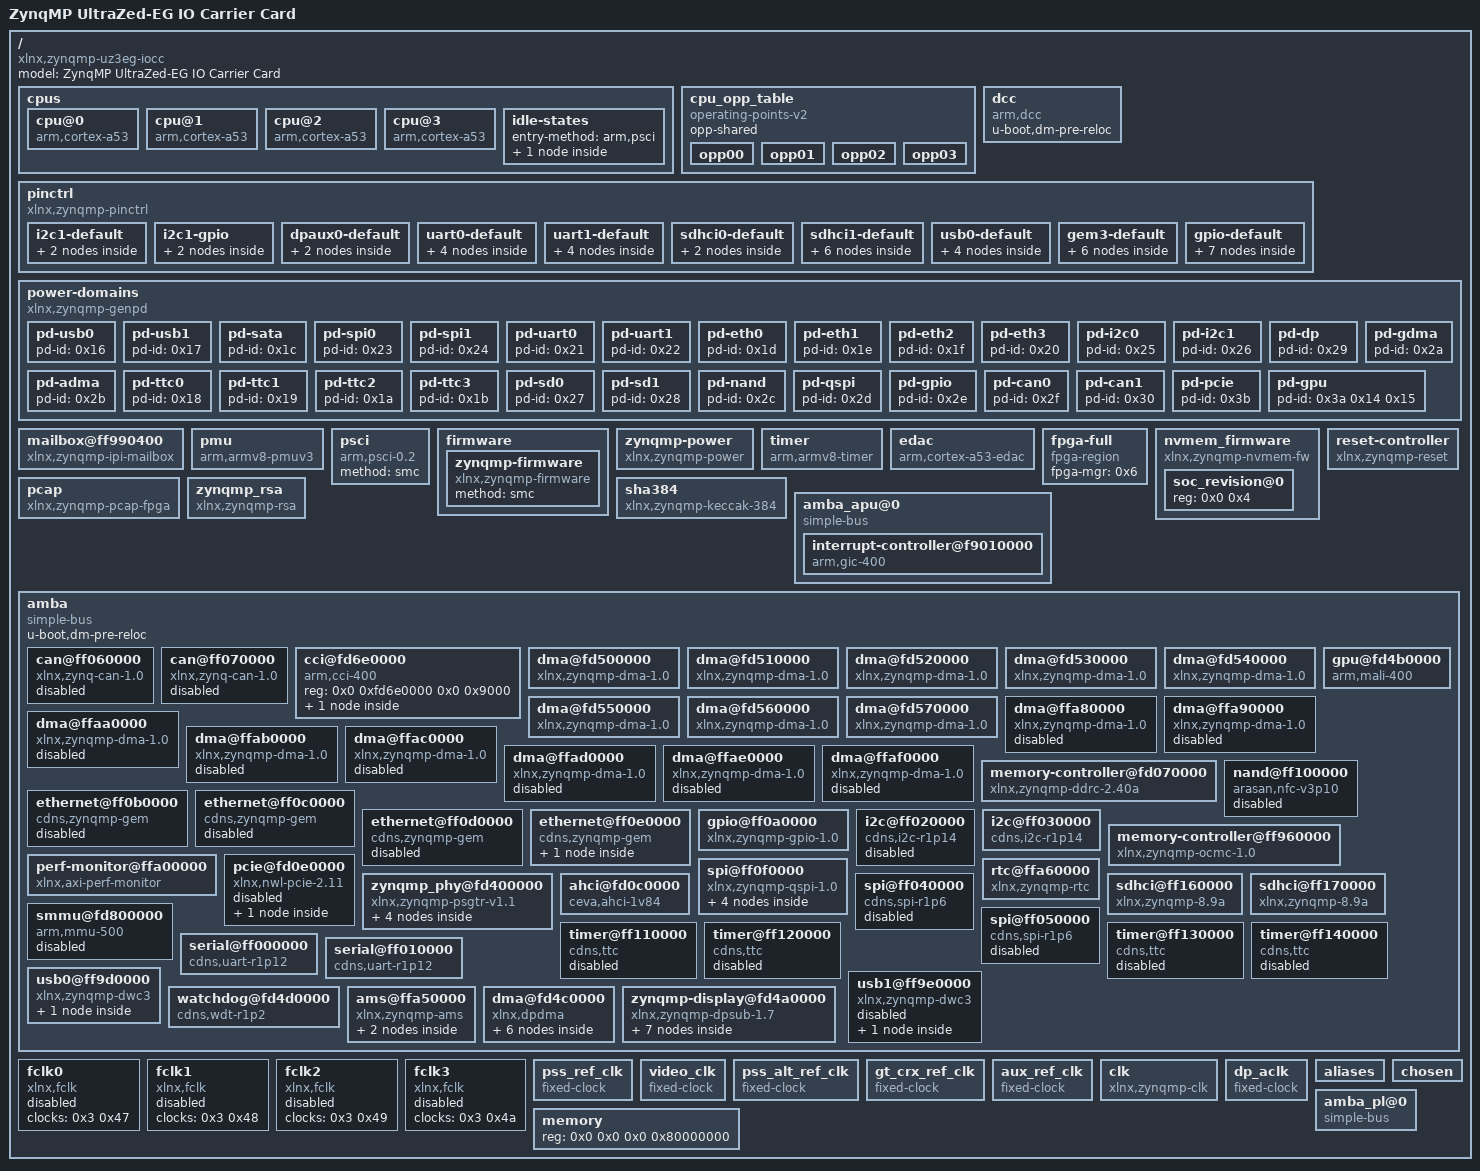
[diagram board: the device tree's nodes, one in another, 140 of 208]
/dts-v1/;

/ {
	compatible = "xlnx,zynqmp-uz3eg-iocc", "xlnx,zynqmp";
	#address-cells = <0x2>;
	#size-cells = <0x2>;
	model = "ZynqMP UltraZed-EG IO Carrier Card";

	cpus {
		#address-cells = <0x1>;
		#size-cells = <0x0>;

		cpu@0 {
			compatible = "arm,cortex-a53", "arm,armv8";
			device_type = "cpu";
			enable-method = "psci";
			operating-points-v2 = <0x1>;
			reg = <0x0>;
			cpu-idle-states = <0x2>;
			clocks = <0x3 0xa>;
			linux,phandle = <0x41>;
			phandle = <0x41>;
		};

		cpu@1 {
			compatible = "arm,cortex-a53", "arm,armv8";
			device_type = "cpu";
			enable-method = "psci";
			reg = <0x1>;
			operating-points-v2 = <0x1>;
			cpu-idle-states = <0x2>;
			linux,phandle = <0x42>;
			phandle = <0x42>;
		};

		cpu@2 {
			compatible = "arm,cortex-a53", "arm,armv8";
			device_type = "cpu";
			enable-method = "psci";
			reg = <0x2>;
			operating-points-v2 = <0x1>;
			cpu-idle-states = <0x2>;
			linux,phandle = <0x43>;
			phandle = <0x43>;
		};

		cpu@3 {
			compatible = "arm,cortex-a53", "arm,armv8";
			device_type = "cpu";
			enable-method = "psci";
			reg = <0x3>;
			operating-points-v2 = <0x1>;
			cpu-idle-states = <0x2>;
			linux,phandle = <0x44>;
			phandle = <0x44>;
		};

		idle-states {
			entry-method = "arm,psci";

			cpu-sleep-0 {
				compatible = "arm,idle-state";
				arm,psci-suspend-param = <0x40000000>;
				local-timer-stop;
				entry-latency-us = <0x12c>;
				exit-latency-us = <0x258>;
				min-residency-us = <0x2710>;
				linux,phandle = <0x2>;
				phandle = <0x2>;
			};
		};
	};

	cpu_opp_table {
		compatible = "operating-points-v2";
		opp-shared;
		linux,phandle = <0x1>;
		phandle = <0x1>;

		opp00 {
			opp-hz = <0x0 0x47868bf4>;
			opp-microvolt = <0xf4240>;
			clock-latency-ns = <0x7a120>;
		};

		opp01 {
			opp-hz = <0x0 0x23c345fa>;
			opp-microvolt = <0xf4240>;
			clock-latency-ns = <0x7a120>;
		};

		opp02 {
			opp-hz = <0x0 0x17d783fc>;
			opp-microvolt = <0xf4240>;
			clock-latency-ns = <0x7a120>;
		};

		opp03 {
			opp-hz = <0x0 0x11e1a2fd>;
			opp-microvolt = <0xf4240>;
			clock-latency-ns = <0x7a120>;
		};
	};

	dcc {
		compatible = "arm,dcc";
		status = "okay";
		u-boot,dm-pre-reloc;
		linux,phandle = <0x45>;
		phandle = <0x45>;
	};

	pinctrl {
		compatible = "xlnx,zynqmp-pinctrl";
		status = "okay";
		linux,phandle = <0x46>;
		phandle = <0x46>;

		i2c1-default {
			linux,phandle = <0x17>;
			phandle = <0x17>;

			mux {
				groups = "i2c1_6_grp";
				function = "i2c1";
			};

			conf {
				groups = "i2c1_6_grp";
				bias-pull-up;
				slew-rate = <0x1>;
				io-standard = <0x1>;
			};
		};

		i2c1-gpio {
			linux,phandle = <0x18>;
			phandle = <0x18>;

			mux {
				groups = "gpio0_24_grp", "gpio0_25_grp";
				function = "gpio0";
			};

			conf {
				groups = "gpio0_24_grp", "gpio0_25_grp";
				slew-rate = <0x1>;
				io-standard = <0x1>;
			};
		};

		dpaux0-default {
			linux,phandle = <0x47>;
			phandle = <0x47>;

			mux {
				groups = "dpaux0_0_grp";
				function = "dpaux0";
			};

			conf {
				groups = "dpaux0_0_grp";
				slew-rate = <0x1>;
				io-standard = <0x1>;
			};
		};

		uart0-default {
			linux,phandle = <0x2d>;
			phandle = <0x2d>;

			mux {
				groups = "uart0_8_grp";
				function = "uart0";
			};

			conf {
				groups = "uart0_8_grp";
				slew-rate = <0x1>;
				io-standard = <0x1>;
			};

			conf-rx {
				pins = "MIO34";
				bias-high-impedance;
			};

			conf-tx {
				pins = "MIO35";
				bias-disable;
			};
		};

		uart1-default {
			linux,phandle = <0x2f>;
			phandle = <0x2f>;

			mux {
				groups = "uart1_8_grp";
				function = "uart1";
			};

			conf {
				groups = "uart1_8_grp";
				slew-rate = <0x1>;
				io-standard = <0x1>;
			};

			conf-rx {
				pins = "MIO33";
				bias-high-impedance;
			};

			conf-tx {
				pins = "MIO32";
				bias-disable;
			};
		};

		sdhci0-default {
			linux,phandle = <0x23>;
			phandle = <0x23>;

			mux {
				groups = "sdio0_0_grp";
				function = "sdio0";
			};

			conf {
				groups = "sdio0_0_grp";
				slew-rate = <0x1>;
				io-standard = <0x1>;
				bias-disable;
			};
		};

		sdhci1-default {
			linux,phandle = <0x25>;
			phandle = <0x25>;

			mux {
				groups = "sdio1_pc_0_grp";
				function = "sdio1_pc";
			};

			conf {
				groups = "sdio1_pc_0_grp";
				slew-rate = <0x1>;
				io-standard = <0x1>;
				bias-disable;
			};

			mux-cd {
				groups = "sdio1_cd_0_grp";
				function = "sdio1_cd";
			};

			conf-cd {
				groups = "sdio1_cd_0_grp";
				bias-high-impedance;
				bias-pull-up;
				slew-rate = <0x1>;
				io-standard = <0x1>;
			};

			mux-wp {
				groups = "sdio1_wp_0_grp";
				function = "sdio1_wp";
			};

			conf-wp {
				groups = "sdio1_wp_0_grp";
				bias-high-impedance;
				bias-pull-up;
				slew-rate = <0x1>;
				io-standard = <0x1>;
			};
		};

		usb0-default {
			linux,phandle = <0x31>;
			phandle = <0x31>;

			mux {
				groups = "usb0_0_grp";
				function = "usb0";
			};

			conf {
				groups = "usb0_0_grp";
				slew-rate = <0x1>;
				io-standard = <0x1>;
			};

			conf-rx {
				pins = "MIO52", "MIO53", "MIO55";
				bias-high-impedance;
			};

			conf-tx {
				pins = "MIO54", "MIO56", "MIO57", "MIO58", "MIO59", "MIO60", "MIO61", "MIO62", "MIO63";
				bias-disable;
			};
		};

		gem3-default {
			linux,phandle = <0x48>;
			phandle = <0x48>;

			mux {
				function = "ethernet3";
				groups = "ethernet3_0_grp";
			};

			conf {
				groups = "ethernet3_0_grp";
				slew-rate = <0x1>;
				io-standard = <0x1>;
			};

			conf-rx {
				pins = "MIO70", "MIO71", "MIO72", "MIO73", "MIO74", "MIO75";
				bias-high-impedance;
				low-power-disable;
			};

			conf-tx {
				pins = "MIO64", "MIO65", "MIO66", "MIO67", "MIO68", "MIO69";
				bias-disable;
				low-power-enable;
			};

			mux-mdio {
				function = "mdio3";
				groups = "mdio3_0_grp";
			};

			conf-mdio {
				groups = "mdio3_0_grp";
				slew-rate = <0x1>;
				io-standard = <0x1>;
				bias-disable;
			};
		};

		gpio-default {
			linux,phandle = <0x14>;
			phandle = <0x14>;

			mux {
				function = "gpio0";
				groups = "gpio0_23_grp", "gpio0_36_grp", "gpio0_37_grp", "gpio0_38_grp", "gpio0_39_grp", "gpio0_40_grp", "gpio0_41_grp", "gpio0_42_grp";
			};

			conf {
				groups = "gpio0_23_grp", "gpio0_36_grp", "gpio0_37_grp", "gpio0_38_grp", "gpio0_39_grp", "gpio0_40_grp", "gpio0_41_grp", "gpio0_42_grp";
				slew-rate = <0x1>;
				io-standard = <0x1>;
			};

			conf-pull-up {
				pins = "MIO23", "MIO26", "MIO31", "MIO36", "MIO37", "MIO38", "MIO39", "MIO40", "MIO41", "MIO42";
				bias-pull-up;
			};

			mux-sw {
				function = "gpio0";
				groups = "gpio0_26_grp";
			};

			conf-sw {
				groups = "gpio0_26_grp";
				slew-rate = <0x1>;
				io-standard = <0x1>;
			};

			mux-led {
				function = "gpio0";
				groups = "gpio0_31_grp";
			};

			conf-led {
				groups = "gpio0_31_grp";
				slew-rate = <0x1>;
				io-standard = <0x1>;
			};
		};
	};

	power-domains {
		compatible = "xlnx,zynqmp-genpd";

		pd-usb0 {
			#power-domain-cells = <0x0>;
			pd-id = <0x16>;
			linux,phandle = <0x30>;
			phandle = <0x30>;
		};

		pd-usb1 {
			#power-domain-cells = <0x0>;
			pd-id = <0x17>;
			linux,phandle = <0x33>;
			phandle = <0x33>;
		};

		pd-sata {
			#power-domain-cells = <0x0>;
			pd-id = <0x1c>;
			linux,phandle = <0x20>;
			phandle = <0x20>;
		};

		pd-spi0 {
			#power-domain-cells = <0x0>;
			pd-id = <0x23>;
			linux,phandle = <0x26>;
			phandle = <0x26>;
		};

		pd-spi1 {
			#power-domain-cells = <0x0>;
			pd-id = <0x24>;
			linux,phandle = <0x27>;
			phandle = <0x27>;
		};

		pd-uart0 {
			#power-domain-cells = <0x0>;
			pd-id = <0x21>;
			linux,phandle = <0x2c>;
			phandle = <0x2c>;
		};

		pd-uart1 {
			#power-domain-cells = <0x0>;
			pd-id = <0x22>;
			linux,phandle = <0x2e>;
			phandle = <0x2e>;
		};

		pd-eth0 {
			#power-domain-cells = <0x0>;
			pd-id = <0x1d>;
			linux,phandle = <0xe>;
			phandle = <0xe>;
		};

		pd-eth1 {
			#power-domain-cells = <0x0>;
			pd-id = <0x1e>;
			linux,phandle = <0xf>;
			phandle = <0xf>;
		};

		pd-eth2 {
			#power-domain-cells = <0x0>;
			pd-id = <0x1f>;
			linux,phandle = <0x10>;
			phandle = <0x10>;
		};

		pd-eth3 {
			#power-domain-cells = <0x0>;
			pd-id = <0x20>;
			linux,phandle = <0x11>;
			phandle = <0x11>;
		};

		pd-i2c0 {
			#power-domain-cells = <0x0>;
			pd-id = <0x25>;
			linux,phandle = <0x15>;
			phandle = <0x15>;
		};

		pd-i2c1 {
			#power-domain-cells = <0x0>;
			pd-id = <0x26>;
			linux,phandle = <0x16>;
			phandle = <0x16>;
		};

		pd-dp {
			#power-domain-cells = <0x0>;
			pd-id = <0x29>;
			linux,phandle = <0x34>;
			phandle = <0x34>;
		};

		pd-gdma {
			#power-domain-cells = <0x0>;
			pd-id = <0x2a>;
			linux,phandle = <0xa>;
			phandle = <0xa>;
		};

		pd-adma {
			#power-domain-cells = <0x0>;
			pd-id = <0x2b>;
			linux,phandle = <0xc>;
			phandle = <0xc>;
		};

		pd-ttc0 {
			#power-domain-cells = <0x0>;
			pd-id = <0x18>;
			linux,phandle = <0x28>;
			phandle = <0x28>;
		};

		pd-ttc1 {
			#power-domain-cells = <0x0>;
			pd-id = <0x19>;
			linux,phandle = <0x29>;
			phandle = <0x29>;
		};

		pd-ttc2 {
			#power-domain-cells = <0x0>;
			pd-id = <0x1a>;
			linux,phandle = <0x2a>;
			phandle = <0x2a>;
		};

		pd-ttc3 {
			#power-domain-cells = <0x0>;
			pd-id = <0x1b>;
			linux,phandle = <0x2b>;
			phandle = <0x2b>;
		};

		pd-sd0 {
			#power-domain-cells = <0x0>;
			pd-id = <0x27>;
			linux,phandle = <0x22>;
			phandle = <0x22>;
		};

		pd-sd1 {
			#power-domain-cells = <0x0>;
			pd-id = <0x28>;
			linux,phandle = <0x24>;
			phandle = <0x24>;
		};

		pd-nand {
			#power-domain-cells = <0x0>;
			pd-id = <0x2c>;
			linux,phandle = <0xd>;
			phandle = <0xd>;
		};

		pd-qspi {
			#power-domain-cells = <0x0>;
			pd-id = <0x2d>;
			linux,phandle = <0x1d>;
			phandle = <0x1d>;
		};

		pd-gpio {
			#power-domain-cells = <0x0>;
			pd-id = <0x2e>;
			linux,phandle = <0x13>;
			phandle = <0x13>;
		};

		pd-can0 {
			#power-domain-cells = <0x0>;
			pd-id = <0x2f>;
			linux,phandle = <0x7>;
			phandle = <0x7>;
		};

		pd-can1 {
			#power-domain-cells = <0x0>;
			pd-id = <0x30>;
			linux,phandle = <0x8>;
			phandle = <0x8>;
		};

		pd-pcie {
			#power-domain-cells = <0x0>;
			pd-id = <0x3b>;
			linux,phandle = <0x1c>;
			phandle = <0x1c>;
		};

		pd-gpu {
			#power-domain-cells = <0x0>;
			pd-id = <0x3a 0x14 0x15>;
			linux,phandle = <0xb>;
			phandle = <0xb>;
		};
	};

	mailbox@ff990400 {
		compatible = "xlnx,zynqmp-ipi-mailbox";
		reg = <0x0 0xff9905c0 0x0 0x20 0x0 0xff9905e0 0x0 0x20 0x0 0xff990e80 0x0 0x20 0x0 0xff990ea0 0x0 0x20>;
		reg-names = "local_request_region", "local_response_region", "remote_request_region", "remote_response_region";
		#mbox-cells = <0x1>;
		xlnx,ipi-ids = <0x0 0x4>;
		interrupt-parent = <0x4>;
		interrupts = <0x0 0x23 0x4>;
		linux,phandle = <0x5>;
		phandle = <0x5>;
	};

	pmu {
		compatible = "arm,armv8-pmuv3";
		interrupt-parent = <0x4>;
		interrupts = <0x0 0x8f 0x4 0x0 0x90 0x4 0x0 0x91 0x4 0x0 0x92 0x4>;
	};

	psci {
		compatible = "arm,psci-0.2";
		method = "smc";
	};

	firmware {

		zynqmp-firmware {
			compatible = "xlnx,zynqmp-firmware";
			method = "smc";
			linux,phandle = <0x49>;
			phandle = <0x49>;
		};
	};

	zynqmp-power {
		compatible = "xlnx,zynqmp-power";
		mboxes = <0x5 0x0 0x5 0x1>;
		mbox-names = "tx", "rx";
		linux,phandle = <0x4a>;
		phandle = <0x4a>;
	};

	timer {
		compatible = "arm,armv8-timer";
		interrupt-parent = <0x4>;
		interrupts = <0x1 0xd 0xf08 0x1 0xe 0xf08 0x1 0xb 0xf08 0x1 0xa 0xf08>;
	};

	edac {
		compatible = "arm,cortex-a53-edac";
	};

	fpga-full {
		compatible = "fpga-region";
		fpga-mgr = <0x6>;
		#address-cells = <0x2>;
		#size-cells = <0x2>;
		linux,phandle = <0x4b>;
		phandle = <0x4b>;
	};

	nvmem_firmware {
		compatible = "xlnx,zynqmp-nvmem-fw";
		#address-cells = <0x1>;
		#size-cells = <0x1>;

		soc_revision@0 {
			reg = <0x0 0x4>;
			linux,phandle = <0x1e>;
			phandle = <0x1e>;
		};
	};

	pcap {
		compatible = "xlnx,zynqmp-pcap-fpga";
		linux,phandle = <0x6>;
		phandle = <0x6>;
	};

	reset-controller {
		compatible = "xlnx,zynqmp-reset";
		#reset-cells = <0x1>;
		linux,phandle = <0x1f>;
		phandle = <0x1f>;
	};

	zynqmp_rsa {
		compatible = "xlnx,zynqmp-rsa";
		linux,phandle = <0x4c>;
		phandle = <0x4c>;
	};

	sha384 {
		compatible = "xlnx,zynqmp-keccak-384";
		linux,phandle = <0x4d>;
		phandle = <0x4d>;
	};

	amba_apu@0 {
		compatible = "simple-bus";
		#address-cells = <0x2>;
		#size-cells = <0x1>;
		ranges = <0x0 0x0 0x0 0x0 0xffffffff>;
		linux,phandle = <0x4e>;
		phandle = <0x4e>;

		interrupt-controller@f9010000 {
			compatible = "arm,gic-400", "arm,cortex-a15-gic";
			#interrupt-cells = <0x3>;
			reg = <0x0 0xf9010000 0x10000 0x0 0xf9020000 0x20000 0x0 0xf9040000 0x20000 0x0 0xf9060000 0x20000>;
			interrupt-controller;
			interrupt-parent = <0x4>;
			interrupts = <0x1 0x9 0xf04>;
			linux,phandle = <0x4>;
			phandle = <0x4>;
		};
	};

	amba {
		compatible = "simple-bus";
		u-boot,dm-pre-reloc;
		#address-cells = <0x2>;
		#size-cells = <0x2>;
		ranges;
		linux,phandle = <0x4f>;
		phandle = <0x4f>;

		can@ff060000 {
			compatible = "xlnx,zynq-can-1.0";
			status = "disabled";
			clock-names = "can_clk", "pclk";
			reg = <0x0 0xff060000 0x0 0x1000>;
			interrupts = <0x0 0x17 0x4>;
			interrupt-parent = <0x4>;
			tx-fifo-depth = <0x40>;
			rx-fifo-depth = <0x40>;
			power-domains = <0x7>;
			clocks = <0x3 0x3f 0x3 0x1f>;
			linux,phandle = <0x50>;
			phandle = <0x50>;
		};

		can@ff070000 {
			compatible = "xlnx,zynq-can-1.0";
			status = "disabled";
			clock-names = "can_clk", "pclk";
			reg = <0x0 0xff070000 0x0 0x1000>;
			interrupts = <0x0 0x18 0x4>;
			interrupt-parent = <0x4>;
			tx-fifo-depth = <0x40>;
			rx-fifo-depth = <0x40>;
			power-domains = <0x8>;
			clocks = <0x3 0x40 0x3 0x1f>;
			linux,phandle = <0x51>;
			phandle = <0x51>;
		};

		cci@fd6e0000 {
			compatible = "arm,cci-400";
			reg = <0x0 0xfd6e0000 0x0 0x9000>;
			ranges = <0x0 0x0 0xfd6e0000 0x10000>;
			#address-cells = <0x1>;
			#size-cells = <0x1>;
			linux,phandle = <0x52>;
			phandle = <0x52>;

			pmu@9000 {
				compatible = "arm,cci-400-pmu,r1";
				reg = <0x9000 0x5000>;
				interrupt-parent = <0x4>;
				interrupts = <0x0 0x7b 0x4 0x0 0x7b 0x4 0x0 0x7b 0x4 0x0 0x7b 0x4 0x0 0x7b 0x4>;
			};
		};

		dma@fd500000 {
			status = "okay";
			compatible = "xlnx,zynqmp-dma-1.0";
			reg = <0x0 0xfd500000 0x0 0x1000>;
			interrupt-parent = <0x4>;
			interrupts = <0x0 0x7c 0x4>;
			clock-names = "clk_main", "clk_apb";
			xlnx,bus-width = <0x80>;
			#stream-id-cells = <0x1>;
			iommus = <0x9 0x14e8>;
			power-domains = <0xa>;
			clocks = <0x3 0x13 0x3 0x1f>;
			linux,phandle = <0x53>;
			phandle = <0x53>;
		};

		dma@fd510000 {
			status = "okay";
			compatible = "xlnx,zynqmp-dma-1.0";
			reg = <0x0 0xfd510000 0x0 0x1000>;
			interrupt-parent = <0x4>;
			interrupts = <0x0 0x7d 0x4>;
			clock-names = "clk_main", "clk_apb";
			xlnx,bus-width = <0x80>;
			#stream-id-cells = <0x1>;
			iommus = <0x9 0x14e9>;
			power-domains = <0xa>;
			clocks = <0x3 0x13 0x3 0x1f>;
			linux,phandle = <0x54>;
			phandle = <0x54>;
		};

		dma@fd520000 {
			status = "okay";
			compatible = "xlnx,zynqmp-dma-1.0";
			reg = <0x0 0xfd520000 0x0 0x1000>;
			interrupt-parent = <0x4>;
			interrupts = <0x0 0x7e 0x4>;
			clock-names = "clk_main", "clk_apb";
			xlnx,bus-width = <0x80>;
			#stream-id-cells = <0x1>;
			iommus = <0x9 0x14ea>;
			power-domains = <0xa>;
			clocks = <0x3 0x13 0x3 0x1f>;
			linux,phandle = <0x55>;
			phandle = <0x55>;
		};

		dma@fd530000 {
			status = "okay";
			compatible = "xlnx,zynqmp-dma-1.0";
			reg = <0x0 0xfd530000 0x0 0x1000>;
			interrupt-parent = <0x4>;
			interrupts = <0x0 0x7f 0x4>;
			clock-names = "clk_main", "clk_apb";
			xlnx,bus-width = <0x80>;
			#stream-id-cells = <0x1>;
			iommus = <0x9 0x14eb>;
			power-domains = <0xa>;
			clocks = <0x3 0x13 0x3 0x1f>;
			linux,phandle = <0x56>;
			phandle = <0x56>;
		};

		dma@fd540000 {
			status = "okay";
			compatible = "xlnx,zynqmp-dma-1.0";
			reg = <0x0 0xfd540000 0x0 0x1000>;
			interrupt-parent = <0x4>;
			interrupts = <0x0 0x80 0x4>;
			clock-names = "clk_main", "clk_apb";
			xlnx,bus-width = <0x80>;
			#stream-id-cells = <0x1>;
			iommus = <0x9 0x14ec>;
			power-domains = <0xa>;
			clocks = <0x3 0x13 0x3 0x1f>;
			linux,phandle = <0x57>;
			phandle = <0x57>;
		};

		dma@fd550000 {
			status = "okay";
			compatible = "xlnx,zynqmp-dma-1.0";
			reg = <0x0 0xfd550000 0x0 0x1000>;
			interrupt-parent = <0x4>;
			interrupts = <0x0 0x81 0x4>;
			clock-names = "clk_main", "clk_apb";
			xlnx,bus-width = <0x80>;
			#stream-id-cells = <0x1>;
			iommus = <0x9 0x14ed>;
			power-domains = <0xa>;
			clocks = <0x3 0x13 0x3 0x1f>;
			linux,phandle = <0x58>;
			phandle = <0x58>;
		};

		dma@fd560000 {
			status = "okay";
			compatible = "xlnx,zynqmp-dma-1.0";
			reg = <0x0 0xfd560000 0x0 0x1000>;
			interrupt-parent = <0x4>;
			interrupts = <0x0 0x82 0x4>;
			clock-names = "clk_main", "clk_apb";
			xlnx,bus-width = <0x80>;
			#stream-id-cells = <0x1>;
			iommus = <0x9 0x14ee>;
			power-domains = <0xa>;
			clocks = <0x3 0x13 0x3 0x1f>;
			linux,phandle = <0x59>;
			phandle = <0x59>;
		};

		dma@fd570000 {
			status = "okay";
			compatible = "xlnx,zynqmp-dma-1.0";
			reg = <0x0 0xfd570000 0x0 0x1000>;
			interrupt-parent = <0x4>;
			interrupts = <0x0 0x83 0x4>;
			clock-names = "clk_main", "clk_apb";
			xlnx,bus-width = <0x80>;
			#stream-id-cells = <0x1>;
			iommus = <0x9 0x14ef>;
			power-domains = <0xa>;
			clocks = <0x3 0x13 0x3 0x1f>;
			linux,phandle = <0x5a>;
			phandle = <0x5a>;
		};

		gpu@fd4b0000 {
			status = "okay";
			compatible = "arm,mali-400", "arm,mali-utgard";
			reg = <0x0 0xfd4b0000 0x0 0x10000>;
			interrupt-parent = <0x4>;
			interrupts = <0x0 0x84 0x4 0x0 0x84 0x4 0x0 0x84 0x4 0x0 0x84 0x4 0x0 0x84 0x4 0x0 0x84 0x4>;
			interrupt-names = "IRQGP", "IRQGPMMU", "IRQPP0", "IRQPPMMU0", "IRQPP1", "IRQPPMMU1";
			clock-names = "gpu", "gpu_pp0", "gpu_pp1";
			power-domains = <0xb>;
			clocks = <0x3 0x18 0x3 0x19 0x3 0x1a>;
			linux,phandle = <0x5b>;
			phandle = <0x5b>;
		};

		dma@ffa80000 {
			status = "disabled";
			compatible = "xlnx,zynqmp-dma-1.0";
			reg = <0x0 0xffa80000 0x0 0x1000>;
			interrupt-parent = <0x4>;
			interrupts = <0x0 0x4d 0x4>;
			clock-names = "clk_main", "clk_apb";
			xlnx,bus-width = <0x40>;
			#stream-id-cells = <0x1>;
			power-domains = <0xc>;
			clocks = <0x3 0x44 0x3 0x1f>;
			linux,phandle = <0x5c>;
			phandle = <0x5c>;
		};

		dma@ffa90000 {
			status = "disabled";
			compatible = "xlnx,zynqmp-dma-1.0";
			reg = <0x0 0xffa90000 0x0 0x1000>;
			interrupt-parent = <0x4>;
			interrupts = <0x0 0x4e 0x4>;
			clock-names = "clk_main", "clk_apb";
			xlnx,bus-width = <0x40>;
			#stream-id-cells = <0x1>;
			power-domains = <0xc>;
			clocks = <0x3 0x44 0x3 0x1f>;
			linux,phandle = <0x5d>;
			phandle = <0x5d>;
		};

		dma@ffaa0000 {
			status = "disabled";
			compatible = "xlnx,zynqmp-dma-1.0";
			reg = <0x0 0xffaa0000 0x0 0x1000>;
			interrupt-parent = <0x4>;
			interrupts = <0x0 0x4f 0x4>;
			clock-names = "clk_main", "clk_apb";
			xlnx,bus-width = <0x40>;
			#stream-id-cells = <0x1>;
			power-domains = <0xc>;
			clocks = <0x3 0x44 0x3 0x1f>;
			linux,phandle = <0x5e>;
			phandle = <0x5e>;
		};

		dma@ffab0000 {
			status = "disabled";
			compatible = "xlnx,zynqmp-dma-1.0";
			reg = <0x0 0xffab0000 0x0 0x1000>;
			interrupt-parent = <0x4>;
			interrupts = <0x0 0x50 0x4>;
			clock-names = "clk_main", "clk_apb";
			xlnx,bus-width = <0x40>;
			#stream-id-cells = <0x1>;
			power-domains = <0xc>;
			clocks = <0x3 0x44 0x3 0x1f>;
			linux,phandle = <0x5f>;
			phandle = <0x5f>;
		};

		dma@ffac0000 {
			status = "disabled";
			compatible = "xlnx,zynqmp-dma-1.0";
			reg = <0x0 0xffac0000 0x0 0x1000>;
			interrupt-parent = <0x4>;
			interrupts = <0x0 0x51 0x4>;
			clock-names = "clk_main", "clk_apb";
			xlnx,bus-width = <0x40>;
			#stream-id-cells = <0x1>;
			power-domains = <0xc>;
			clocks = <0x3 0x44 0x3 0x1f>;
			linux,phandle = <0x60>;
			phandle = <0x60>;
		};

		dma@ffad0000 {
			status = "disabled";
			compatible = "xlnx,zynqmp-dma-1.0";
			reg = <0x0 0xffad0000 0x0 0x1000>;
			interrupt-parent = <0x4>;
			interrupts = <0x0 0x52 0x4>;
			clock-names = "clk_main", "clk_apb";
			xlnx,bus-width = <0x40>;
			#stream-id-cells = <0x1>;
			power-domains = <0xc>;
			clocks = <0x3 0x44 0x3 0x1f>;
			linux,phandle = <0x61>;
			phandle = <0x61>;
		};

		dma@ffae0000 {
			status = "disabled";
			compatible = "xlnx,zynqmp-dma-1.0";
			reg = <0x0 0xffae0000 0x0 0x1000>;
			interrupt-parent = <0x4>;
			interrupts = <0x0 0x53 0x4>;
			clock-names = "clk_main", "clk_apb";
			xlnx,bus-width = <0x40>;
			#stream-id-cells = <0x1>;
			power-domains = <0xc>;
			clocks = <0x3 0x44 0x3 0x1f>;
			linux,phandle = <0x62>;
			phandle = <0x62>;
		};

		dma@ffaf0000 {
			status = "disabled";
			compatible = "xlnx,zynqmp-dma-1.0";
			reg = <0x0 0xffaf0000 0x0 0x1000>;
			interrupt-parent = <0x4>;
			interrupts = <0x0 0x54 0x4>;
			clock-names = "clk_main", "clk_apb";
			xlnx,bus-width = <0x40>;
			#stream-id-cells = <0x1>;
			power-domains = <0xc>;
			clocks = <0x3 0x44 0x3 0x1f>;
			linux,phandle = <0x63>;
			phandle = <0x63>;
		};

		memory-controller@fd070000 {
			compatible = "xlnx,zynqmp-ddrc-2.40a";
			reg = <0x0 0xfd070000 0x0 0x30000>;
			interrupt-parent = <0x4>;
			interrupts = <0x0 0x70 0x4>;
			linux,phandle = <0x64>;
			phandle = <0x64>;
		};

		nand@ff100000 {
			compatible = "arasan,nfc-v3p10";
			status = "disabled";
			reg = <0x0 0xff100000 0x0 0x1000>;
			clock-names = "clk_sys", "clk_flash";
			interrupt-parent = <0x4>;
			interrupts = <0x0 0xe 0x4>;
			#address-cells = <0x1>;
			#size-cells = <0x0>;
			#stream-id-cells = <0x1>;
			iommus = <0x9 0x872>;
			power-domains = <0xd>;
			clocks = <0x3 0x3c 0x3 0x1f>;
			linux,phandle = <0x65>;
			phandle = <0x65>;
		};

		ethernet@ff0b0000 {
			compatible = "cdns,zynqmp-gem", "cdns,gem";
			status = "disabled";
			interrupt-parent = <0x4>;
			interrupts = <0x0 0x39 0x4 0x0 0x39 0x4>;
			reg = <0x0 0xff0b0000 0x0 0x1000>;
			clock-names = "pclk", "hclk", "tx_clk", "rx_clk", "tsu_clk";
			#address-cells = <0x1>;
			#size-cells = <0x0>;
			#stream-id-cells = <0x1>;
			iommus = <0x9 0x874>;
			power-domains = <0xe>;
			clocks = <0x3 0x1f 0x3 0x31 0x3 0x2d 0x3 0x31 0x3 0x2c>;
			linux,phandle = <0x66>;
			phandle = <0x66>;
		};

		ethernet@ff0c0000 {
			compatible = "cdns,zynqmp-gem", "cdns,gem";
			status = "disabled";
			interrupt-parent = <0x4>;
			interrupts = <0x0 0x3b 0x4 0x0 0x3b 0x4>;
			reg = <0x0 0xff0c0000 0x0 0x1000>;
			clock-names = "pclk", "hclk", "tx_clk", "rx_clk", "tsu_clk";
			#address-cells = <0x1>;
			#size-cells = <0x0>;
			#stream-id-cells = <0x1>;
			iommus = <0x9 0x875>;
			power-domains = <0xf>;
			clocks = <0x3 0x1f 0x3 0x32 0x3 0x2e 0x3 0x32 0x3 0x2c>;
			linux,phandle = <0x67>;
			phandle = <0x67>;
		};

		ethernet@ff0d0000 {
			compatible = "cdns,zynqmp-gem", "cdns,gem";
			status = "disabled";
			interrupt-parent = <0x4>;
			interrupts = <0x0 0x3d 0x4 0x0 0x3d 0x4>;
			reg = <0x0 0xff0d0000 0x0 0x1000>;
			clock-names = "pclk", "hclk", "tx_clk", "rx_clk", "tsu_clk";
			#address-cells = <0x1>;
			#size-cells = <0x0>;
			#stream-id-cells = <0x1>;
			iommus = <0x9 0x876>;
			power-domains = <0x10>;
			clocks = <0x3 0x1f 0x3 0x33 0x3 0x2f 0x3 0x33 0x3 0x2c>;
			linux,phandle = <0x68>;
			phandle = <0x68>;
		};

		ethernet@ff0e0000 {
			compatible = "cdns,zynqmp-gem", "cdns,gem";
			status = "okay";
			interrupt-parent = <0x4>;
			interrupts = <0x0 0x3f 0x4 0x0 0x3f 0x4>;
			reg = <0x0 0xff0e0000 0x0 0x1000>;
			clock-names = "pclk", "hclk", "tx_clk", "rx_clk", "tsu_clk";
			#address-cells = <0x1>;
			#size-cells = <0x0>;
			#stream-id-cells = <0x1>;
			iommus = <0x9 0x877>;
			power-domains = <0x11>;
			clocks = <0x3 0x1f 0x3 0x34 0x3 0x30 0x3 0x34 0x3 0x2c>;
			xlnx,ptp-enet-clock = <0x0>;
			phy-mode = "rgmii-id";
			phy-handle = <0x12>;
			linux,phandle = <0x69>;
			phandle = <0x69>;

			phy@9 {
				reg = <0x9>;
				ti,rx-internal-delay = <0x8>;
				ti,tx-internal-delay = <0xa>;
				ti,fifo-depth = <0x1>;
				ti,rxctrl-strap-worka;
				linux,phandle = <0x12>;
				phandle = <0x12>;
			};
		};

		gpio@ff0a0000 {
			compatible = "xlnx,zynqmp-gpio-1.0";
			status = "okay";
			#gpio-cells = <0x2>;
			interrupt-parent = <0x4>;
			interrupts = <0x0 0x10 0x4>;
			interrupt-controller;
			#interrupt-cells = <0x2>;
			reg = <0x0 0xff0a0000 0x0 0x1000>;
			gpio-controller;
			power-domains = <0x13>;
			clocks = <0x3 0x1f>;
			pinctrl-names = "default";
			pinctrl-0 = <0x14>;
			linux,phandle = <0x19>;
			phandle = <0x19>;
		};

		i2c@ff020000 {
			compatible = "cdns,i2c-r1p14", "cdns,i2c-r1p10";
			status = "disabled";
			interrupt-parent = <0x4>;
			interrupts = <0x0 0x11 0x4>;
			reg = <0x0 0xff020000 0x0 0x1000>;
			#address-cells = <0x1>;
			#size-cells = <0x0>;
			power-domains = <0x15>;
			clocks = <0x3 0x3d>;
			linux,phandle = <0x6a>;
			phandle = <0x6a>;
		};

		i2c@ff030000 {
			compatible = "cdns,i2c-r1p14", "cdns,i2c-r1p10";
			status = "okay";
			interrupt-parent = <0x4>;
			interrupts = <0x0 0x12 0x4>;
			reg = <0x0 0xff030000 0x0 0x1000>;
			#address-cells = <0x1>;
			#size-cells = <0x0>;
			power-domains = <0x16>;
			clocks = <0x3 0x3e>;
			clock-frequency = <0x61a80>;
			pinctrl-names = "default", "gpio";
			pinctrl-0 = <0x17>;
			pinctrl-1 = <0x18>;
			scl-gpios = <0x19 0x18 0x0>;
			sda-gpios = <0x19 0x19 0x0>;
			linux,phandle = <0x6b>;
			phandle = <0x6b>;
		};

		memory-controller@ff960000 {
			compatible = "xlnx,zynqmp-ocmc-1.0";
			reg = <0x0 0xff960000 0x0 0x1000>;
			interrupt-parent = <0x4>;
			interrupts = <0x0 0xa 0x4>;
			linux,phandle = <0x6c>;
			phandle = <0x6c>;
		};

		perf-monitor@ffa00000 {
			compatible = "xlnx,axi-perf-monitor";
			reg = <0x0 0xffa00000 0x0 0x10000>;
			interrupts = <0x0 0x19 0x4>;
			interrupt-parent = <0x4>;
			xlnx,enable-profile = <0x0>;
			xlnx,enable-trace = <0x0>;
			xlnx,num-monitor-slots = <0x4>;
			xlnx,enable-event-count = <0x1>;
			xlnx,enable-event-log = <0x1>;
			xlnx,have-sampled-metric-cnt = <0x1>;
			xlnx,num-of-counters = <0x8>;
			xlnx,metric-count-width = <0x20>;
			xlnx,metrics-sample-count-width = <0x20>;
			xlnx,global-count-width = <0x20>;
			xlnx,metric-count-scale = <0x1>;
			clocks = <0x3 0x1f>;
			linux,phandle = <0x6d>;
			phandle = <0x6d>;
		};

		pcie@fd0e0000 {
			compatible = "xlnx,nwl-pcie-2.11";
			status = "disabled";
			#address-cells = <0x3>;
			#size-cells = <0x2>;
			#interrupt-cells = <0x1>;
			msi-controller;
			device_type = "pci";
			interrupt-parent = <0x4>;
			interrupts = <0x0 0x76 0x4 0x0 0x75 0x4 0x0 0x74 0x4 0x0 0x73 0x4 0x0 0x72 0x4>;
			interrupt-names = "misc", "dummy", "intx", "msi1", "msi0";
			msi-parent = <0x1a>;
			reg = <0x0 0xfd0e0000 0x0 0x1000 0x0 0xfd480000 0x0 0x1000 0x80 0x0 0x0 0x1000000>;
			reg-names = "breg", "pcireg", "cfg";
			ranges = <0x2000000 0x0 0xe0000000 0x0 0xe0000000 0x0 0x10000000 0x43000000 0x6 0x0 0x6 0x0 0x2 0x0>;
			bus-range = <0x0 0xff>;
			interrupt-map-mask = <0x0 0x0 0x0 0x7>;
			interrupt-map = <0x0 0x0 0x0 0x1 0x1b 0x1 0x0 0x0 0x0 0x2 0x1b 0x2 0x0 0x0 0x0 0x3 0x1b 0x3 0x0 0x0 0x0 0x4 0x1b 0x4>;
			power-domains = <0x1c>;
			clocks = <0x3 0x17>;
			linux,phandle = <0x1a>;
			phandle = <0x1a>;

			legacy-interrupt-controller {
				interrupt-controller;
				#address-cells = <0x0>;
				#interrupt-cells = <0x1>;
				linux,phandle = <0x1b>;
				phandle = <0x1b>;
			};
		};

		spi@ff0f0000 {
			u-boot,dm-pre-reloc;
			compatible = "xlnx,zynqmp-qspi-1.0";
			status = "okay";
			clock-names = "ref_clk", "pclk";
			interrupts = <0x0 0xf 0x4>;
			interrupt-parent = <0x4>;
			num-cs = <0x1>;
			reg = <0x0 0xff0f0000 0x0 0x1000 0x0 0xc0000000 0x0 0x8000000>;
			#address-cells = <0x1>;
			#size-cells = <0x0>;
			#stream-id-cells = <0x1>;
			iommus = <0x9 0x873>;
			power-domains = <0x1d>;
			clocks = <0x3 0x35 0x3 0x1f>;
			is-dual = <0x1>;
			spi-rx-bus-width = <0x4>;
			spi-tx-bus-width = <0x4>;
			linux,phandle = <0x6e>;
			phandle = <0x6e>;

			flash@0 {
				compatible = "n25q512a", "micron,m25p80";
				spi-tx-bus-width = <0x1>;
				spi-rx-bus-width = <0x4>;
				reg = <0x0>;
				#address-cells = <0x1>;
				#size-cells = <0x1>;
				spi-max-frequency = <0x66ff300>;

				partition@0x00000000 {
					label = "boot";
					reg = <0x0 0x100000>;
				};

				partition@0x00100000 {
					label = "bootenv";
					reg = <0x100000 0x40000>;
				};

				partition@0x00140000 {
					label = "kernel";
					reg = <0x140000 0x1600000>;
				};
			};
		};

		rtc@ffa60000 {
			compatible = "xlnx,zynqmp-rtc";
			status = "okay";
			reg = <0x0 0xffa60000 0x0 0x100>;
			interrupt-parent = <0x4>;
			interrupts = <0x0 0x1a 0x4 0x0 0x1b 0x4>;
			interrupt-names = "alarm", "sec";
			calibration = <0x8000>;
			linux,phandle = <0x6f>;
			phandle = <0x6f>;
		};

		zynqmp_phy@fd400000 {
			compatible = "xlnx,zynqmp-psgtr-v1.1";
			status = "okay";
			reg = <0x0 0xfd400000 0x0 0x40000 0x0 0xfd3d0000 0x0 0x1000>;
			reg-names = "serdes", "siou";
			nvmem-cells = <0x1e>;
			nvmem-cell-names = "soc_revision";
			resets = <0x1f 0x10 0x1f 0x3b 0x1f 0x3c 0x1f 0x3d 0x1f 0x3e 0x1f 0x3f 0x1f 0x40 0x1f 0x3 0x1f 0x1d 0x1f 0x1e 0x1f 0x1f 0x1f 0x20>;
			reset-names = "sata_rst", "usb0_crst", "usb1_crst", "usb0_hibrst", "usb1_hibrst", "usb0_apbrst", "usb1_apbrst", "dp_rst", "gem0_rst", "gem1_rst", "gem2_rst", "gem3_rst";
			linux,phandle = <0x70>;
			phandle = <0x70>;

			lane0 {
				#phy-cells = <0x4>;
				linux,phandle = <0x32>;
				phandle = <0x32>;
			};

			lane1 {
				#phy-cells = <0x4>;
				linux,phandle = <0x21>;
				phandle = <0x21>;
			};

			lane2 {
				#phy-cells = <0x4>;
				linux,phandle = <0x37>;
				phandle = <0x37>;
			};

			lane3 {
				#phy-cells = <0x4>;
				linux,phandle = <0x36>;
				phandle = <0x36>;
			};
		};

		ahci@fd0c0000 {
			compatible = "ceva,ahci-1v84";
			status = "okay";
			reg = <0x0 0xfd0c0000 0x0 0x2000>;
			interrupt-parent = <0x4>;
			interrupts = <0x0 0x85 0x4>;
			power-domains = <0x20>;
			#stream-id-cells = <0x4>;
			iommus = <0x9 0x4c0 0x9 0x4c1 0x9 0x4c2 0x9 0x4c3>;
			clocks = <0x3 0x16>;
			ceva,p0-cominit-params = <0x18401828>;
			ceva,p0-comwake-params = <0x614080e>;
			ceva,p0-burst-params = <0x13084a06>;
			ceva,p0-retry-params = <0x96a43ffc>;
			ceva,p1-cominit-params = <0x18401828>;
			ceva,p1-comwake-params = <0x614080e>;
			ceva,p1-burst-params = <0x13084a06>;
			ceva,p1-retry-params = <0x96a43ffc>;
			phy-names = "sata-phy";
			phys = <0x21 0x1 0x1 0x1 0x7735940>;
			linux,phandle = <0x71>;
			phandle = <0x71>;
		};

		sdhci@ff160000 {
			u-boot,dm-pre-reloc;
			compatible = "xlnx,zynqmp-8.9a", "arasan,sdhci-8.9a";
			status = "okay";
			interrupt-parent = <0x4>;
			interrupts = <0x0 0x30 0x4>;
			reg = <0x0 0xff160000 0x0 0x1000>;
			clock-names = "clk_xin", "clk_ahb";
			xlnx,device_id = <0x0>;
			#stream-id-cells = <0x1>;
			iommus = <0x9 0x870>;
			power-domains = <0x22>;
			nvmem-cells = <0x1e>;
			nvmem-cell-names = "soc_revision";
			clocks = <0x3 0x36 0x3 0x1f>;
			clock-frequency = <0xbebba30>;
			pinctrl-names = "default";
			pinctrl-0 = <0x23>;
			xlnx,mio_bank = <0x0>;
			disable-wp;
			linux,phandle = <0x72>;
			phandle = <0x72>;
		};

		sdhci@ff170000 {
			u-boot,dm-pre-reloc;
			compatible = "xlnx,zynqmp-8.9a", "arasan,sdhci-8.9a";
			status = "okay";
			interrupt-parent = <0x4>;
			interrupts = <0x0 0x31 0x4>;
			reg = <0x0 0xff170000 0x0 0x1000>;
			clock-names = "clk_xin", "clk_ahb";
			xlnx,device_id = <0x1>;
			#stream-id-cells = <0x1>;
			iommus = <0x9 0x871>;
			power-domains = <0x24>;
			nvmem-cells = <0x1e>;
			nvmem-cell-names = "soc_revision";
			clocks = <0x3 0x37 0x3 0x1f>;
			clock-frequency = <0xbebba30>;
			pinctrl-names = "default";
			pinctrl-0 = <0x25>;
			xlnx,mio_bank = <0x1>;
			max-frequency = <0x2faf080>;
			no-1-8-v;
			disable-wp;
			linux,phandle = <0x73>;
			phandle = <0x73>;
		};

		smmu@fd800000 {
			compatible = "arm,mmu-500";
			reg = <0x0 0xfd800000 0x0 0x20000>;
			#iommu-cells = <0x1>;
			status = "disabled";
			#global-interrupts = <0x1>;
			interrupt-parent = <0x4>;
			interrupts = <0x0 0x9b 0x4 0x0 0x9b 0x4 0x0 0x9b 0x4 0x0 0x9b 0x4 0x0 0x9b 0x4 0x0 0x9b 0x4 0x0 0x9b 0x4 0x0 0x9b 0x4 0x0 0x9b 0x4 0x0 0x9b 0x4 0x0 0x9b 0x4 0x0 0x9b 0x4 0x0 0x9b 0x4 0x0 0x9b 0x4 0x0 0x9b 0x4 0x0 0x9b 0x4 0x0 0x9b 0x4>;
			linux,phandle = <0x9>;
			phandle = <0x9>;
		};

		spi@ff040000 {
			compatible = "cdns,spi-r1p6";
			status = "disabled";
			interrupt-parent = <0x4>;
			interrupts = <0x0 0x13 0x4>;
			reg = <0x0 0xff040000 0x0 0x1000>;
			clock-names = "ref_clk", "pclk";
			#address-cells = <0x1>;
			#size-cells = <0x0>;
			power-domains = <0x26>;
			clocks = <0x3 0x3a 0x3 0x1f>;
			linux,phandle = <0x74>;
			phandle = <0x74>;
		};

		spi@ff050000 {
			compatible = "cdns,spi-r1p6";
			status = "disabled";
			interrupt-parent = <0x4>;
			interrupts = <0x0 0x14 0x4>;
			reg = <0x0 0xff050000 0x0 0x1000>;
			clock-names = "ref_clk", "pclk";
			#address-cells = <0x1>;
			#size-cells = <0x0>;
			power-domains = <0x27>;
			clocks = <0x3 0x3b 0x3 0x1f>;
			linux,phandle = <0x75>;
			phandle = <0x75>;
		};

		timer@ff110000 {
			compatible = "cdns,ttc";
			status = "disabled";
			interrupt-parent = <0x4>;
			interrupts = <0x0 0x24 0x4 0x0 0x25 0x4 0x0 0x26 0x4>;
			reg = <0x0 0xff110000 0x0 0x1000>;
			timer-width = <0x20>;
			power-domains = <0x28>;
			clocks = <0x3 0x1f>;
			linux,phandle = <0x76>;
			phandle = <0x76>;
		};

		timer@ff120000 {
			compatible = "cdns,ttc";
			status = "disabled";
			interrupt-parent = <0x4>;
			interrupts = <0x0 0x27 0x4 0x0 0x28 0x4 0x0 0x29 0x4>;
			reg = <0x0 0xff120000 0x0 0x1000>;
			timer-width = <0x20>;
			power-domains = <0x29>;
			clocks = <0x3 0x1f>;
			linux,phandle = <0x77>;
			phandle = <0x77>;
		};

		timer@ff130000 {
			compatible = "cdns,ttc";
			status = "disabled";
			interrupt-parent = <0x4>;
			interrupts = <0x0 0x2a 0x4 0x0 0x2b 0x4 0x0 0x2c 0x4>;
			reg = <0x0 0xff130000 0x0 0x1000>;
			timer-width = <0x20>;
			power-domains = <0x2a>;
			clocks = <0x3 0x1f>;
			linux,phandle = <0x78>;
			phandle = <0x78>;
		};

		timer@ff140000 {
			compatible = "cdns,ttc";
			status = "disabled";
			interrupt-parent = <0x4>;
			interrupts = <0x0 0x2d 0x4 0x0 0x2e 0x4 0x0 0x2f 0x4>;
			reg = <0x0 0xff140000 0x0 0x1000>;
			timer-width = <0x20>;
			power-domains = <0x2b>;
			clocks = <0x3 0x1f>;
			linux,phandle = <0x79>;
			phandle = <0x79>;
		};

		serial@ff000000 {
			u-boot,dm-pre-reloc;
			compatible = "cdns,uart-r1p12", "xlnx,xuartps";
			status = "okay";
			interrupt-parent = <0x4>;
			interrupts = <0x0 0x15 0x4>;
			reg = <0x0 0xff000000 0x0 0x1000>;
			clock-names = "uart_clk", "pclk";
			power-domains = <0x2c>;
			clocks = <0x3 0x38 0x3 0x1f>;
			device_type = "serial";
			port-number = <0x0>;
			pinctrl-names = "default";
			pinctrl-0 = <0x2d>;
			linux,phandle = <0x7a>;
			phandle = <0x7a>;
		};

		serial@ff010000 {
			u-boot,dm-pre-reloc;
			compatible = "cdns,uart-r1p12", "xlnx,xuartps";
			status = "okay";
			interrupt-parent = <0x4>;
			interrupts = <0x0 0x16 0x4>;
			reg = <0x0 0xff010000 0x0 0x1000>;
			clock-names = "uart_clk", "pclk";
			power-domains = <0x2e>;
			clocks = <0x3 0x39 0x3 0x1f>;
			device_type = "serial";
			port-number = <0x1>;
			pinctrl-names = "default";
			pinctrl-0 = <0x2f>;
			linux,phandle = <0x7b>;
			phandle = <0x7b>;
		};

		usb0@ff9d0000 {
			#address-cells = <0x2>;
			#size-cells = <0x2>;
			status = "okay";
			compatible = "xlnx,zynqmp-dwc3";
			reg = <0x0 0xff9d0000 0x0 0x100>;
			clock-names = "bus_clk", "ref_clk";
			power-domains = <0x30>;
			ranges;
			nvmem-cells = <0x1e>;
			nvmem-cell-names = "soc_revision";
			clocks = <0x3 0x20 0x3 0x22>;
			pinctrl-names = "default";
			pinctrl-0 = <0x31>;
			linux,phandle = <0x7c>;
			phandle = <0x7c>;

			dwc3@fe200000 {
				compatible = "snps,dwc3";
				status = "okay";
				reg = <0x0 0xfe200000 0x0 0x40000>;
				interrupt-parent = <0x4>;
				interrupts = <0x0 0x41 0x4 0x0 0x45 0x4 0x0 0x4b 0x4>;
				#stream-id-cells = <0x1>;
				iommus = <0x9 0x860>;
				snps,quirk-frame-length-adjustment = <0x20>;
				snps,refclk_fladj;
				snps,enable_guctl1_resume_quirk;
				snps,enable_guctl1_ipd_quirk;
				snps,xhci-stream-quirk;
				dr_mode = "host";
				snps,usb3_lpm_capable;
				phy-names = "usb3-phy";
				phys = <0x32 0x4 0x0 0x0 0x18cba80>;
				maximum-speed = "super-speed";
				linux,phandle = <0x7d>;
				phandle = <0x7d>;
			};
		};

		usb1@ff9e0000 {
			#address-cells = <0x2>;
			#size-cells = <0x2>;
			status = "disabled";
			compatible = "xlnx,zynqmp-dwc3";
			reg = <0x0 0xff9e0000 0x0 0x100>;
			clock-names = "bus_clk", "ref_clk";
			power-domains = <0x33>;
			ranges;
			nvmem-cells = <0x1e>;
			nvmem-cell-names = "soc_revision";
			clocks = <0x3 0x21 0x3 0x22>;
			linux,phandle = <0x7e>;
			phandle = <0x7e>;

			dwc3@fe300000 {
				compatible = "snps,dwc3";
				status = "disabled";
				reg = <0x0 0xfe300000 0x0 0x40000>;
				interrupt-parent = <0x4>;
				interrupts = <0x0 0x46 0x4 0x0 0x4a 0x4 0x0 0x4c 0x4>;
				#stream-id-cells = <0x1>;
				iommus = <0x9 0x861>;
				snps,quirk-frame-length-adjustment = <0x20>;
				snps,refclk_fladj;
				snps,enable_guctl1_resume_quirk;
				snps,enable_guctl1_ipd_quirk;
				snps,xhci-stream-quirk;
				linux,phandle = <0x7f>;
				phandle = <0x7f>;
			};
		};

		watchdog@fd4d0000 {
			compatible = "cdns,wdt-r1p2";
			status = "okay";
			interrupt-parent = <0x4>;
			interrupts = <0x0 0x71 0x1>;
			reg = <0x0 0xfd4d0000 0x0 0x1000>;
			timeout-sec = <0xa>;
			clocks = <0x3 0x4b>;
			linux,phandle = <0x80>;
			phandle = <0x80>;
		};

		ams@ffa50000 {
			compatible = "xlnx,zynqmp-ams";
			status = "okay";
			interrupt-parent = <0x4>;
			interrupts = <0x0 0x38 0x4>;
			interrupt-names = "ams-irq";
			reg = <0x0 0xffa50000 0x0 0x800>;
			reg-names = "ams-base";
			#address-cells = <0x2>;
			#size-cells = <0x2>;
			#io-channel-cells = <0x1>;
			ranges;
			clocks = <0x3 0x46>;
			linux,phandle = <0x81>;
			phandle = <0x81>;

			ams_ps@ffa50800 {
				compatible = "xlnx,zynqmp-ams-ps";
				status = "okay";
				reg = <0x0 0xffa50800 0x0 0x400>;
				linux,phandle = <0x82>;
				phandle = <0x82>;
			};

			ams_pl@ffa50c00 {
				compatible = "xlnx,zynqmp-ams-pl";
				status = "okay";
				reg = <0x0 0xffa50c00 0x0 0x400>;
				linux,phandle = <0x83>;
				phandle = <0x83>;
			};
		};

		dma@fd4c0000 {
			compatible = "xlnx,dpdma";
			status = "okay";
			reg = <0x0 0xfd4c0000 0x0 0x1000>;
			interrupts = <0x0 0x7a 0x4>;
			interrupt-parent = <0x4>;
			clock-names = "axi_clk";
			power-domains = <0x34>;
			dma-channels = <0x6>;
			#dma-cells = <0x1>;
			clocks = <0x3 0x14>;
			linux,phandle = <0x38>;
			phandle = <0x38>;

			dma-video0channel {
				compatible = "xlnx,video0";
			};

			dma-video1channel {
				compatible = "xlnx,video1";
			};

			dma-video2channel {
				compatible = "xlnx,video2";
			};

			dma-graphicschannel {
				compatible = "xlnx,graphics";
			};

			dma-audio0channel {
				compatible = "xlnx,audio0";
			};

			dma-audio1channel {
				compatible = "xlnx,audio1";
			};
		};

		zynqmp-display@fd4a0000 {
			compatible = "xlnx,zynqmp-dpsub-1.7";
			status = "okay";
			reg = <0x0 0xfd4a0000 0x0 0x1000 0x0 0xfd4aa000 0x0 0x1000 0x0 0xfd4ab000 0x0 0x1000 0x0 0xfd4ac000 0x0 0x1000>;
			reg-names = "dp", "blend", "av_buf", "aud";
			interrupts = <0x0 0x77 0x4>;
			interrupt-parent = <0x4>;
			clock-names = "dp_apb_clk", "dp_aud_clk", "dp_vtc_pixel_clk_in";
			power-domains = <0x34>;
			clocks = <0x35 0x3 0x11 0x3 0x10>;
			phy-names = "dp-phy0", "dp-phy1";
			phys = <0x36 0x5 0x0 0x3 0x19bfcc0 0x37 0x5 0x1 0x3 0x19bfcc0>;
			linux,phandle = <0x84>;
			phandle = <0x84>;

			vid-layer {
				dma-names = "vid0", "vid1", "vid2";
				dmas = <0x38 0x0 0x38 0x1 0x38 0x2>;
			};

			gfx-layer {
				dma-names = "gfx0";
				dmas = <0x38 0x3>;
			};

			i2c-bus {
			};

			zynqmp_dp_snd_codec0 {
				compatible = "xlnx,dp-snd-codec";
				clock-names = "aud_clk";
				clocks = <0x3 0x11>;
				status = "okey";
				linux,phandle = <0x3b>;
				phandle = <0x3b>;
			};

			zynqmp_dp_snd_pcm0 {
				compatible = "xlnx,dp-snd-pcm";
				dmas = <0x38 0x4>;
				dma-names = "tx";
				status = "okey";
				linux,phandle = <0x39>;
				phandle = <0x39>;
			};

			zynqmp_dp_snd_pcm1 {
				compatible = "xlnx,dp-snd-pcm";
				dmas = <0x38 0x5>;
				dma-names = "tx";
				status = "okey";
				linux,phandle = <0x3a>;
				phandle = <0x3a>;
			};

			zynqmp_dp_snd_card {
				compatible = "xlnx,dp-snd-card";
				xlnx,dp-snd-pcm = <0x39 0x3a>;
				xlnx,dp-snd-codec = <0x3b>;
				status = "okey";
				linux,phandle = <0x85>;
				phandle = <0x85>;
			};
		};
	};

	fclk0 {
		status = "disabled";
		compatible = "xlnx,fclk";
		clocks = <0x3 0x47>;
		linux,phandle = <0x86>;
		phandle = <0x86>;
	};

	fclk1 {
		status = "disabled";
		compatible = "xlnx,fclk";
		clocks = <0x3 0x48>;
		linux,phandle = <0x87>;
		phandle = <0x87>;
	};

	fclk2 {
		status = "disabled";
		compatible = "xlnx,fclk";
		clocks = <0x3 0x49>;
		linux,phandle = <0x88>;
		phandle = <0x88>;
	};

	fclk3 {
		status = "disabled";
		compatible = "xlnx,fclk";
		clocks = <0x3 0x4a>;
		linux,phandle = <0x89>;
		phandle = <0x89>;
	};

	pss_ref_clk {
		u-boot,dm-pre-reloc;
		compatible = "fixed-clock";
		#clock-cells = <0x0>;
		clock-frequency = <0x1fca055>;
		linux,phandle = <0x3c>;
		phandle = <0x3c>;
	};

	video_clk {
		u-boot,dm-pre-reloc;
		compatible = "fixed-clock";
		#clock-cells = <0x0>;
		clock-frequency = <0x19bfcc0>;
		linux,phandle = <0x3d>;
		phandle = <0x3d>;
	};

	pss_alt_ref_clk {
		u-boot,dm-pre-reloc;
		compatible = "fixed-clock";
		#clock-cells = <0x0>;
		clock-frequency = <0x0>;
		linux,phandle = <0x3e>;
		phandle = <0x3e>;
	};

	gt_crx_ref_clk {
		u-boot,dm-pre-reloc;
		compatible = "fixed-clock";
		#clock-cells = <0x0>;
		clock-frequency = <0x66ff300>;
		linux,phandle = <0x40>;
		phandle = <0x40>;
	};

	aux_ref_clk {
		u-boot,dm-pre-reloc;
		compatible = "fixed-clock";
		#clock-cells = <0x0>;
		clock-frequency = <0x19bfcc0>;
		linux,phandle = <0x3f>;
		phandle = <0x3f>;
	};

	clk {
		u-boot,dm-pre-reloc;
		#clock-cells = <0x1>;
		compatible = "xlnx,zynqmp-clk";
		clocks = <0x3c 0x3d 0x3e 0x3f 0x40>;
		clock-names = "pss_ref_clk", "video_clk", "pss_alt_ref_clk", "aux_ref_clk", "gt_crx_ref_clk";
		linux,phandle = <0x3>;
		phandle = <0x3>;
	};

	dp_aclk {
		compatible = "fixed-clock";
		#clock-cells = <0x0>;
		clock-frequency = <0x5f5e100>;
		clock-accuracy = <0x64>;
		linux,phandle = <0x35>;
		phandle = <0x35>;
	};

	aliases {
		ethernet0 = "/amba/ethernet@ff0e0000";
		serial0 = "/amba/serial@ff000000";
		serial1 = "/amba/serial@ff010000";
		spi0 = "/amba/spi@ff0f0000";
	};

	chosen {
		bootargs = "earlycon clk_ignore_unused";
		stdout-path = "serial0:115200n8";
	};

	memory {
		device_type = "memory";
		reg = <0x0 0x0 0x0 0x80000000>;
	};

	amba_pl@0 {
		#address-cells = <0x2>;
		#size-cells = <0x2>;
		compatible = "simple-bus";
		ranges;
		linux,phandle = <0x8a>;
		phandle = <0x8a>;
	};

	__symbols__ {
		cpu0 = "/cpus/cpu@0";
		cpu1 = "/cpus/cpu@1";
		cpu2 = "/cpus/cpu@2";
		cpu3 = "/cpus/cpu@3";
		CPU_SLEEP_0 = "/cpus/idle-states/cpu-sleep-0";
		cpu_opp_table = "/cpu_opp_table";
		dcc = "/dcc";
		pinctrl0 = "/pinctrl";
		pinctrl_i2c1_default = "/pinctrl/i2c1-default";
		pinctrl_i2c1_gpio = "/pinctrl/i2c1-gpio";
		pinctrl_dpaux0_default = "/pinctrl/dpaux0-default";
		pinctrl_uart0_default = "/pinctrl/uart0-default";
		pinctrl_uart1_default = "/pinctrl/uart1-default";
		pinctrl_sdhci0_default = "/pinctrl/sdhci0-default";
		pinctrl_sdhci1_default = "/pinctrl/sdhci1-default";
		pinctrl_usb0_default = "/pinctrl/usb0-default";
		pinctrl_gem3_default = "/pinctrl/gem3-default";
		pinctrl_gpio_default = "/pinctrl/gpio-default";
		pd_usb0 = "/power-domains/pd-usb0";
		pd_usb1 = "/power-domains/pd-usb1";
		pd_sata = "/power-domains/pd-sata";
		pd_spi0 = "/power-domains/pd-spi0";
		pd_spi1 = "/power-domains/pd-spi1";
		pd_uart0 = "/power-domains/pd-uart0";
		pd_uart1 = "/power-domains/pd-uart1";
		pd_eth0 = "/power-domains/pd-eth0";
		pd_eth1 = "/power-domains/pd-eth1";
		pd_eth2 = "/power-domains/pd-eth2";
		pd_eth3 = "/power-domains/pd-eth3";
		pd_i2c0 = "/power-domains/pd-i2c0";
		pd_i2c1 = "/power-domains/pd-i2c1";
		pd_dp = "/power-domains/pd-dp";
		pd_gdma = "/power-domains/pd-gdma";
		pd_adma = "/power-domains/pd-adma";
		pd_ttc0 = "/power-domains/pd-ttc0";
		pd_ttc1 = "/power-domains/pd-ttc1";
		pd_ttc2 = "/power-domains/pd-ttc2";
		pd_ttc3 = "/power-domains/pd-ttc3";
		pd_sd0 = "/power-domains/pd-sd0";
		pd_sd1 = "/power-domains/pd-sd1";
		pd_nand = "/power-domains/pd-nand";
		pd_qspi = "/power-domains/pd-qspi";
		pd_gpio = "/power-domains/pd-gpio";
		pd_can0 = "/power-domains/pd-can0";
		pd_can1 = "/power-domains/pd-can1";
		pd_pcie = "/power-domains/pd-pcie";
		pd_gpu = "/power-domains/pd-gpu";
		ipi_mailbox_pmu1 = "/mailbox@ff990400";
		zynqmp_firmware = "/firmware/zynqmp-firmware";
		zynqmp_power = "/zynqmp-power";
		fpga_full = "/fpga-full";
		soc_revision = "/nvmem_firmware/soc_revision@0";
		pcap = "/pcap";
		rst = "/reset-controller";
		xlnx_rsa = "/zynqmp_rsa";
		xlnx_keccak_384 = "/sha384";
		amba_apu = "/amba_apu@0";
		gic = "/amba_apu@0/interrupt-controller@f9010000";
		amba = "/amba";
		can0 = "/amba/can@ff060000";
		can1 = "/amba/can@ff070000";
		cci = "/amba/cci@fd6e0000";
		fpd_dma_chan1 = "/amba/dma@fd500000";
		fpd_dma_chan2 = "/amba/dma@fd510000";
		fpd_dma_chan3 = "/amba/dma@fd520000";
		fpd_dma_chan4 = "/amba/dma@fd530000";
		fpd_dma_chan5 = "/amba/dma@fd540000";
		fpd_dma_chan6 = "/amba/dma@fd550000";
		fpd_dma_chan7 = "/amba/dma@fd560000";
		fpd_dma_chan8 = "/amba/dma@fd570000";
		gpu = "/amba/gpu@fd4b0000";
		lpd_dma_chan1 = "/amba/dma@ffa80000";
		lpd_dma_chan2 = "/amba/dma@ffa90000";
		lpd_dma_chan3 = "/amba/dma@ffaa0000";
		lpd_dma_chan4 = "/amba/dma@ffab0000";
		lpd_dma_chan5 = "/amba/dma@ffac0000";
		lpd_dma_chan6 = "/amba/dma@ffad0000";
		lpd_dma_chan7 = "/amba/dma@ffae0000";
		lpd_dma_chan8 = "/amba/dma@ffaf0000";
		mc = "/amba/memory-controller@fd070000";
		nand0 = "/amba/nand@ff100000";
		gem0 = "/amba/ethernet@ff0b0000";
		gem1 = "/amba/ethernet@ff0c0000";
		gem2 = "/amba/ethernet@ff0d0000";
		gem3 = "/amba/ethernet@ff0e0000";
		phy9 = "/amba/ethernet@ff0e0000/phy@9";
		gpio = "/amba/gpio@ff0a0000";
		i2c0 = "/amba/i2c@ff020000";
		i2c1 = "/amba/i2c@ff030000";
		ocm = "/amba/memory-controller@ff960000";
		perf_monitor_ocm = "/amba/perf-monitor@ffa00000";
		pcie = "/amba/pcie@fd0e0000";
		pcie_intc = "/amba/pcie@fd0e0000/legacy-interrupt-controller";
		qspi = "/amba/spi@ff0f0000";
		rtc = "/amba/rtc@ffa60000";
		serdes = "/amba/zynqmp_phy@fd400000";
		lane0 = "/amba/zynqmp_phy@fd400000/lane0";
		lane1 = "/amba/zynqmp_phy@fd400000/lane1";
		lane2 = "/amba/zynqmp_phy@fd400000/lane2";
		lane3 = "/amba/zynqmp_phy@fd400000/lane3";
		sata = "/amba/ahci@fd0c0000";
		sdhci0 = "/amba/sdhci@ff160000";
		sdhci1 = "/amba/sdhci@ff170000";
		smmu = "/amba/smmu@fd800000";
		spi0 = "/amba/spi@ff040000";
		spi1 = "/amba/spi@ff050000";
		ttc0 = "/amba/timer@ff110000";
		ttc1 = "/amba/timer@ff120000";
		ttc2 = "/amba/timer@ff130000";
		ttc3 = "/amba/timer@ff140000";
		uart0 = "/amba/serial@ff000000";
		uart1 = "/amba/serial@ff010000";
		usb0 = "/amba/usb0@ff9d0000";
		dwc3_0 = "/amba/usb0@ff9d0000/dwc3@fe200000";
		usb1 = "/amba/usb1@ff9e0000";
		dwc3_1 = "/amba/usb1@ff9e0000/dwc3@fe300000";
		watchdog0 = "/amba/watchdog@fd4d0000";
		xilinx_ams = "/amba/ams@ffa50000";
		ams_ps = "/amba/ams@ffa50000/ams_ps@ffa50800";
		ams_pl = "/amba/ams@ffa50000/ams_pl@ffa50c00";
		xlnx_dpdma = "/amba/dma@fd4c0000";
		zynqmp_dpsub = "/amba/zynqmp-display@fd4a0000";
		zynqmp_dp_snd_codec0 = "/amba/zynqmp-display@fd4a0000/zynqmp_dp_snd_codec0";
		zynqmp_dp_snd_pcm0 = "/amba/zynqmp-display@fd4a0000/zynqmp_dp_snd_pcm0";
		zynqmp_dp_snd_pcm1 = "/amba/zynqmp-display@fd4a0000/zynqmp_dp_snd_pcm1";
		zynqmp_dp_snd_card0 = "/amba/zynqmp-display@fd4a0000/zynqmp_dp_snd_card";
		fclk0 = "/fclk0";
		fclk1 = "/fclk1";
		fclk2 = "/fclk2";
		fclk3 = "/fclk3";
		pss_ref_clk = "/pss_ref_clk";
		video_clk = "/video_clk";
		pss_alt_ref_clk = "/pss_alt_ref_clk";
		gt_crx_ref_clk = "/gt_crx_ref_clk";
		aux_ref_clk = "/aux_ref_clk";
		clk = "/clk";
		dp_aclk = "/dp_aclk";
		amba_pl = "/amba_pl@0";
	};
};
